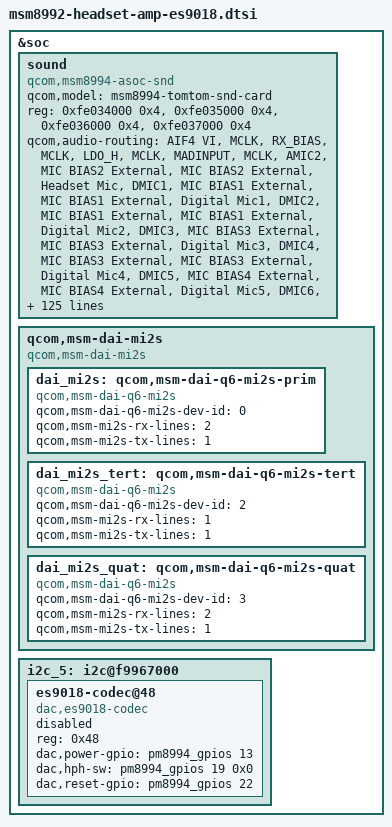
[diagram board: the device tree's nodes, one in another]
/* Copyright (c) 2014, The Linux Foundation. All rights reserved.
 *
 * This program is free software; you can redistribute it and/or modify
 * it under the terms of the GNU General Public License version 2 and
 * only version 2 as published by the Free Software Foundation.
 *
 * This program is distributed in the hope that it will be useful,
 * but WITHOUT ANY WARRANTY; without even the implied warranty of
 * MERCHANTABILITY or FITNESS FOR A PARTICULAR PURPOSE.  See the
 * GNU General Public License for more details.
 */

&soc {
	sound {
		compatible = "qcom,msm8994-asoc-snd";
		qcom,model = "msm8994-tomtom-snd-card";
		reg = <0xfe034000 0x4>,
		      <0xfe035000 0x4>,
		      <0xfe036000 0x4>,
		      <0xfe037000 0x4>;
		reg-names = "lpaif_pri_mode_muxsel",
			    "lpaif_sec_mode_muxsel",
			    "lpaif_tert_mode_muxsel",
			    "lpaif_quat_mode_muxsel";

		qcom,audio-routing =
			"AIF4 VI", "MCLK",
			"RX_BIAS", "MCLK",
			"LDO_H", "MCLK",
			"MADINPUT", "MCLK",
			"AMIC2", "MIC BIAS2 External",
			"MIC BIAS2 External", "Headset Mic",
			"DMIC1", "MIC BIAS1 External",
			"MIC BIAS1 External", "Digital Mic1",
			"DMIC2", "MIC BIAS1 External",
			"MIC BIAS1 External", "Digital Mic2",
			"DMIC3", "MIC BIAS3 External",
			"MIC BIAS3 External", "Digital Mic3",
			"DMIC4", "MIC BIAS3 External",
			"MIC BIAS3 External", "Digital Mic4",
			"DMIC5", "MIC BIAS4 External",
			"MIC BIAS4 External", "Digital Mic5",
			"DMIC6", "MIC BIAS4 External",
			"MIC BIAS4 External", "Digital Mic6";

		asoc-cpu =
		<&dai_pri_auxpcm>, <&dai_sec_auxpcm>, <&dai_hdmi>, <&dai_mi2s>, <&dai_mi2s_tert>, <&dai_mi2s_quat>,
		<&sb_0_rx>, <&sb_0_tx>, <&sb_1_rx>, <&sb_1_tx>,
		<&sb_2_rx>, <&sb_2_tx>, <&sb_3_rx>, <&sb_3_tx>,
		<&sb_4_rx>, <&sb_4_tx>, <&sb_5_tx>, <&bt_sco_rx>,
		<&bt_sco_tx>, <&int_fm_rx>, <&int_fm_tx>, <&afe_pcm_rx>,
		<&afe_pcm_tx>, <&afe_proxy_rx>, <&afe_proxy_tx>,
		<&incall_record_rx>, <&incall_record_tx>, <&incall_music_rx>, <&incall_music2_rx>;

		asoc-cpu-names = "msm-dai-q6-auxpcm.1", "msm-dai-q6-auxpcm.2",
		"msm-dai-q6-hdmi.8", "msm-dai-q6-mi2s.0", "msm-dai-q6-mi2s.2", "msm-dai-q6-mi2s.3",
		"msm-dai-q6-dev.16384", "msm-dai-q6-dev.16385",
		"msm-dai-q6-dev.16386", "msm-dai-q6-dev.16387",
		"msm-dai-q6-dev.16388", "msm-dai-q6-dev.16389",
		"msm-dai-q6-dev.16390", "msm-dai-q6-dev.16391",
		"msm-dai-q6-dev.16392", "msm-dai-q6-dev.16393",
		"msm-dai-q6-dev.16395", "msm-dai-q6-dev.12288",
		"msm-dai-q6-dev.12289", "msm-dai-q6-dev.12292",
		"msm-dai-q6-dev.12293", "msm-dai-q6-dev.224",
		"msm-dai-q6-dev.225", "msm-dai-q6-dev.241",
		"msm-dai-q6-dev.240", "msm-dai-q6-dev.32771",
		"msm-dai-q6-dev.32772", "msm-dai-q6-dev.32773",
		"msm-dai-q6-dev.32770";

		clock-names = "osr_clk";
		clocks = <&clock_rpm clk_div_clk1>;
		qcom,cdc-mclk-gpios = <&pm8994_gpios 15 0>;
		qcom,tomtom-mclk-clk-freq = <9600000>;
		pinctrl-names = "pin_state_0",
		"pin_state_1",
		"pin_state_2",
		"pin_state_3",
		"pin_state_4",
		"pin_state_5",
		"pin_state_6",
		"pin_state_7",
		"pin_state_8",
		"pin_state_9",
		"pin_state_10",
		"pin_state_11",
		"pin_state_12",
		"pin_state_13",
		"pin_state_14",
		"pin_state_15";
		pinctrl-0 = <&pri_mi2s_sleep>, <&pri_mi2s_sd0_sleep>, <&quat_mi2s_sleep>, <&quat_mi2s_mclk_sleep>, <&quat_mi2s_sd0_sleep>, <&quat_mi2s_sd1_sleep>, <&sec_aux_pcm_sleep>, <&sec_aux_pcm_din_sleep>, <&tert_mi2s_sleep>, <&tert_mi2s_sd0_sleep>;
		pinctrl-1 = <&pri_mi2s_sleep>, <&pri_mi2s_sd0_sleep>, <&quat_mi2s_sleep>, <&quat_mi2s_mclk_sleep>, <&quat_mi2s_sd0_sleep>, <&quat_mi2s_sd1_sleep>, <&sec_aux_pcm_active>, <&sec_aux_pcm_din_active>, <&tert_mi2s_sleep>, <&tert_mi2s_sd0_sleep>;
		pinctrl-2 = <&pri_mi2s_active>, <&pri_mi2s_sd0_active>, <&quat_mi2s_sleep>, <&quat_mi2s_mclk_sleep>, <&quat_mi2s_sd0_sleep>, <&quat_mi2s_sd1_sleep>, <&sec_aux_pcm_sleep>, <&sec_aux_pcm_din_sleep>, <&tert_mi2s_sleep>, <&tert_mi2s_sd0_sleep>;
		pinctrl-3 = <&pri_mi2s_active>, <&pri_mi2s_sd0_active>, <&quat_mi2s_sleep>, <&quat_mi2s_mclk_sleep>, <&quat_mi2s_sd0_sleep>, <&quat_mi2s_sd1_sleep>, <&sec_aux_pcm_active>, <&sec_aux_pcm_din_active>, <&tert_mi2s_sleep>, <&tert_mi2s_sd0_sleep>;
		pinctrl-4 = <&pri_mi2s_sleep>, <&pri_mi2s_sd0_sleep>, <&quat_mi2s_active>, <&quat_mi2s_mclk_active>, <&quat_mi2s_sd0_active>, <&quat_mi2s_sd1_active>, <&sec_aux_pcm_sleep>, <&sec_aux_pcm_din_sleep>, <&tert_mi2s_sleep>, <&tert_mi2s_sd0_sleep>;
		pinctrl-5 = <&pri_mi2s_sleep>, <&pri_mi2s_sd0_sleep>, <&quat_mi2s_active>, <&quat_mi2s_mclk_active>, <&quat_mi2s_sd0_active>, <&quat_mi2s_sd1_active>, <&sec_aux_pcm_active>, <&sec_aux_pcm_din_active>, <&tert_mi2s_sleep>, <&tert_mi2s_sd0_sleep>;
		pinctrl-6 = <&pri_mi2s_active>, <&pri_mi2s_sd0_active>, <&quat_mi2s_active>, <&quat_mi2s_mclk_active>, <&quat_mi2s_sd0_active>, <&quat_mi2s_sd1_active>, <&sec_aux_pcm_sleep>, <&sec_aux_pcm_din_sleep>, <&tert_mi2s_sleep>, <&tert_mi2s_sd0_sleep>;
		pinctrl-7 = <&pri_mi2s_active>, <&pri_mi2s_sd0_active>, <&quat_mi2s_active>, <&quat_mi2s_mclk_active>, <&quat_mi2s_sd0_active>, <&quat_mi2s_sd1_active>, <&sec_aux_pcm_active>, <&sec_aux_pcm_din_active>, <&tert_mi2s_sleep>, <&tert_mi2s_sd0_sleep>;
		pinctrl-8 = <&pri_mi2s_sleep>, <&pri_mi2s_sd0_sleep>, <&quat_mi2s_sleep>, <&quat_mi2s_mclk_sleep>, <&quat_mi2s_sd0_sleep>, <&quat_mi2s_sd1_sleep>, <&sec_aux_pcm_sleep>, <&sec_aux_pcm_din_sleep>, <&tert_mi2s_active>, <&tert_mi2s_sd0_active>;
		pinctrl-9 = <&pri_mi2s_sleep>, <&pri_mi2s_sd0_sleep>, <&quat_mi2s_sleep>, <&quat_mi2s_mclk_sleep>, <&quat_mi2s_sd0_sleep>, <&quat_mi2s_sd1_sleep>, <&sec_aux_pcm_active>, <&sec_aux_pcm_din_active>, <&tert_mi2s_active>, <&tert_mi2s_sd0_active>;
		pinctrl-10 = <&pri_mi2s_active>, <&pri_mi2s_sd0_active>, <&quat_mi2s_sleep>, <&quat_mi2s_mclk_sleep>, <&quat_mi2s_sd0_sleep>, <&quat_mi2s_sd1_sleep>, <&sec_aux_pcm_sleep>, <&sec_aux_pcm_din_sleep>, <&tert_mi2s_active>, <&tert_mi2s_sd0_active>;
		pinctrl-11 = <&pri_mi2s_active>, <&pri_mi2s_sd0_active>, <&quat_mi2s_sleep>, <&quat_mi2s_mclk_sleep>, <&quat_mi2s_sd0_sleep>, <&quat_mi2s_sd1_sleep>, <&sec_aux_pcm_active>, <&sec_aux_pcm_din_active>, <&tert_mi2s_active>, <&tert_mi2s_sd0_active>;
		pinctrl-12 = <&pri_mi2s_sleep>, <&pri_mi2s_sd0_sleep>, <&quat_mi2s_active>, <&quat_mi2s_mclk_active>, <&quat_mi2s_sd0_active>, <&quat_mi2s_sd1_active>, <&sec_aux_pcm_sleep>, <&sec_aux_pcm_din_sleep>, <&tert_mi2s_active>, <&tert_mi2s_sd0_active>;
		pinctrl-13 = <&pri_mi2s_sleep>, <&pri_mi2s_sd0_sleep>, <&quat_mi2s_active>, <&quat_mi2s_mclk_active>, <&quat_mi2s_sd0_active>, <&quat_mi2s_sd1_active>, <&sec_aux_pcm_active>, <&sec_aux_pcm_din_active>, <&tert_mi2s_active>, <&tert_mi2s_sd0_active>;
		pinctrl-14 = <&pri_mi2s_active>, <&pri_mi2s_sd0_active>, <&quat_mi2s_active>, <&quat_mi2s_mclk_active>, <&quat_mi2s_sd0_active>, <&quat_mi2s_sd1_active>, <&sec_aux_pcm_sleep>, <&sec_aux_pcm_din_sleep>, <&tert_mi2s_active>, <&tert_mi2s_sd0_active>;
		pinctrl-15 = <&pri_mi2s_active>, <&pri_mi2s_sd0_active>, <&quat_mi2s_active>, <&quat_mi2s_mclk_active>, <&quat_mi2s_sd0_active>, <&quat_mi2s_sd1_active>, <&sec_aux_pcm_active>, <&sec_aux_pcm_din_active>, <&tert_mi2s_active>, <&tert_mi2s_sd0_active>;
		qcom,cdc-micbias2-headset-only;
		qcom,us-euro-gpios = <&pm8994_mpps 2 0>;
/*		qcom,mbhc-audio-jack-type = "4-pole-jack"; */
		qcom,hdmi-audio-rx;
		asoc-codec = <&stub_codec>, <&hdmi_audio>;
		asoc-codec-names = "msm-stub-codec.1", "msm-hdmi-audio-codec-rx";

	};

	qcom,msm-dai-mi2s {
		compatible = "qcom,msm-dai-mi2s";
		dai_mi2s: qcom,msm-dai-q6-mi2s-prim {
			compatible = "qcom,msm-dai-q6-mi2s";
			qcom,msm-dai-q6-mi2s-dev-id = <0>;
			qcom,msm-mi2s-rx-lines = <2>;
			qcom,msm-mi2s-tx-lines = <1>;
		};
		dai_mi2s_tert: qcom,msm-dai-q6-mi2s-tert {
			compatible = "qcom,msm-dai-q6-mi2s";
			qcom,msm-dai-q6-mi2s-dev-id = <2>;
			qcom,msm-mi2s-rx-lines = <1>;
			qcom,msm-mi2s-tx-lines = <1>;
		};
		dai_mi2s_quat: qcom,msm-dai-q6-mi2s-quat {
			compatible = "qcom,msm-dai-q6-mi2s";
			qcom,msm-dai-q6-mi2s-dev-id = <3>;
			qcom,msm-mi2s-rx-lines = <2>;
			qcom,msm-mi2s-tx-lines = <1>;
		};
	};

	i2c_5: i2c@f9967000 {
		es9018-codec@48 {
			compatible = "dac,es9018-codec";
			status = "disable";
			reg = <0x48>;
			dac,power-gpio = <&pm8994_gpios 13 0x0>;
			dac,hph-sw = <&pm8994_gpios 19 0x0>;
			dac,reset-gpio = <&pm8994_gpios 22 0x0>;
		};
	};
};
